# M031AE_v1 register map
File version: 1.0
Registers are 32-bit, read-write, reset 0x0 unless marked. A register's access mark holds for its fields unless they carry their own. Offsets are from the block's base; [hi:lo] are bit positions; 'fields as' and 'values as' point back to an identical list.

## EBI — EBI Register Map
Base 0x40010000
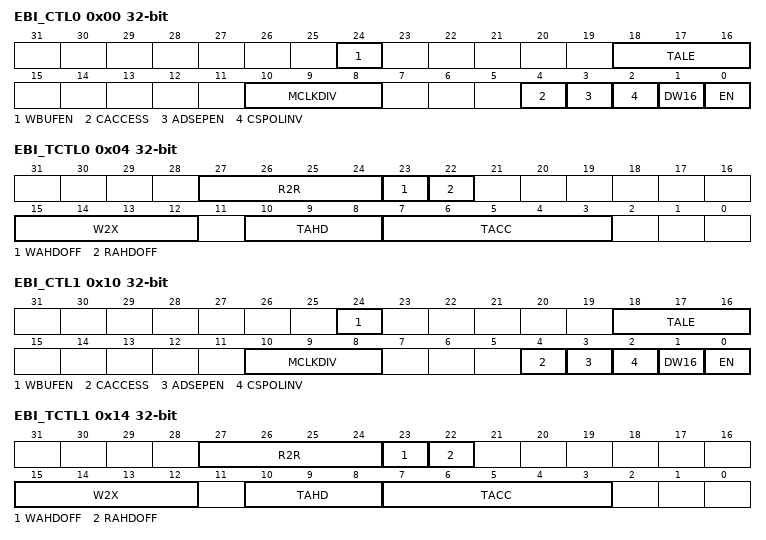
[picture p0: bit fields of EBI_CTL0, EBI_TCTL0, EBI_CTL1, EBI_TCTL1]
0x00 EBI_CTL0 — External Bus Interface Bank0 Control Register
  [24] WBUFEN — EBI Write Buffer Enable Bit. Note: This bit is only available in EBI_CTL0 register.
    0=EBI write buffer Disabled; 1=EBI write buffer Enabled
  [18:16] TALE — Extend Time of ALE. The EBI_ALE high pulse period (tALE) to latch the address can be controlled by TALE. Note: This field is only available in EBI_CTL0 register.
  [10:8] MCLKDIV — External Output Clock Divider. The frequency of EBI output clock (MCLK) is controlled by MCLKDIV as follow:
    0=HCLK/1; 1=HCLK/2; 2=HCLK/4; 3=HCLK/8; 4=HCLK/16; 5=HCLK/32; 6=HCLK/64; 7=HCLK/128
  [4] CACCESS — Continuous Data Access Mode. When Continuous access mode is enabled, the tASU, tALE and tLHD cycles are bypass for continuous data transfer request.
    0=Continuous data access mode Disabled; 1=Continuous data access mode Enabled
  [3] ADSEPEN — EBI Address/Data Bus Separating Mode Enable Bit
    0=Address/Data Bus Separating Mode Disabled; 1=Address/Data Bus Separating Mode Enabled
  [2] CSPOLINV — Chip Select Pin Polar Inverse. This bit defines the active level of EBI chip select pin (EBI_nCS).
    0=Chip select pin (EBI_nCS) is active low; 1=Chip select pin (EBI_nCS) is active high
  [1] DW16 — EBI Data Width 16-bit Select. This bit defines if the EBI data width is 8-bit or 16-bit.
    0=EBI data width is 8-bit; 1=EBI data width is 16-bit
  [0] EN — EBI Enable Bit. This bit is the functional enable bit for EBI.
    0=EBI function Disabled; 1=EBI function Enabled
0x04 EBI_TCTL0 — External Bus Interface Bank0 Timing Control Register
  [27:24] R2R — Idle Cycle Between Read-to-read. This field defines the number of R2R idle cycle. Note: When read action is finished and the next action is going to read, R2R idle cycle is inserted and EBI_nCS return to idle state.
  [23] WAHDOFF — Access Hold Time Disable Control When Write
    0=Data Access Hold Time (tAHD) during EBI writing Enabled; 1=Data Access Hold Time (tAHD) during EBI writing Disabled
  [22] RAHDOFF — Access Hold Time Disable Control When Read
    0=Data Access Hold Time (tAHD) during EBI reading Enabled; 1=Data Access Hold Time (tAHD) during EBI reading Disabled
  [15:12] W2X — Idle Cycle After Write. This field defines the number of W2X idle cycle. Note: When write action is finished, W2X idle cycle is inserted and EBI_nCS return to idle state.
  [10:8] TAHD — EBI Data Access Hold Time. TAHD defines data access hold time (tAHD).
  [7:3] TACC — EBI Data Access Time. TACC defines data access time (tACC).
0x10 EBI_CTL1 — External Bus Interface Bank1 Control Register
  fields as EBI_CTL0
0x14 EBI_TCTL1 — External Bus Interface Bank1 Timing Control Register
  fields as EBI_TCTL0

## CRC — CRC Register Map
Base 0x40031000
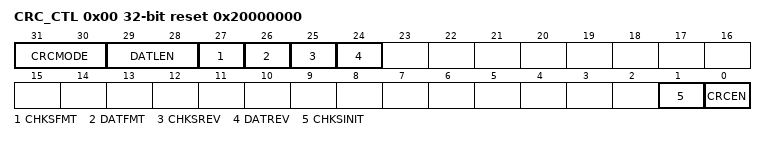
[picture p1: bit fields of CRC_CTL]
0x00 CRC_CTL reset 0x20000000 — CRC Control Register
  [31:30] CRCMODE — CRC Polynomial Mode. This field indicates the CRC operation polynomial mode.
    0=CRC-CCITT Polynomial mode; 1=CRC-8 Polynomial mode; 2=CRC-16 Polynomial mode; 3=CRC-32 Polynomial mode
  [29:28] DATLEN — CPU Write Data Length. This field indicates the write data length. Note: When the write data length is 8-bit mode, the valid data in CRC_DAT register is only DATA[7:0] bits; if the write data length is 16-bit mode, the valid data in CRC_DAT register is only DATA[15:0].
    0=Data length is 8-bit mode; 1=Data length is 16-bit mode. Data length is 32-bit mode
  [27] CHKSFMT — Checksum 1's Complement. This bit is used to enable the 1's complement function for checksum result in CRC_CHECKSUM register.
    0=1's complement for CRC checksum Disabled; 1=1's complement for CRC checksum Enabled
  [26] DATFMT — Write Data 1's Complement. This bit is used to enable the 1's complement function for write data value in CRC_DAT register.
    0=1's complement for CRC writes data in Disabled; 1=1's complement for CRC writes data in Enabled
  [25] CHKSREV — Checksum Bit Order Reverse. This bit is used to enable the bit order reverse function for checksum result in CRC_CHECKSUM register. Note: If the checksum result is 0xDD7B0F2E, the bit order reverse for CRC checksum is 0x74F0DEBB.
    0=Bit order reverse for CRC checksum Disabled; 1=Bit order reverse for CRC checksum Enabled
  [24] DATREV — Write Data Bit Order Reverse. This bit is used to enable the bit order reverse function per byte for write data value in CRC_DAT register. Note: If the write data is 0xAABBCCDD, the bit order reverse for CRC write data in is 0x55DD33BB.
    0=Bit order reversed for CRC write data in Disabled; 1=Bit order reversed for CRC write data in Enabled (per byte)
  [1] CHKSINIT — Checksum Initialization. Note: This bit will be cleared automatically.
    0=No effect; 1=Initial checksum value by auto reload CRC_SEED register value to CRC_CHECKSUM register value
  [0] CRCEN — CRC Channel Enable Bit
    0=No effect; 1=CRC operation Enabled
0x04 CRC_DAT — CRC Write Data Register
  [31:0] DATA — CRC Write Data Bits. User can write data directly by CPU mode or use PDMA function to write data to this field to perform CRC operation. Note: When the write data length is 8-bit mode, the valid data in CRC_DAT register is only DATA[7:0] bits; if the write data length is 16-bit mode, the valid data in CRC_DAT register is only DATA[15:0].
0x08 CRC_SEED reset 0xFFFFFFFF
  [31:0] SEED — CRC Seed Value. This field indicates the CRC seed value. Note: This field will be reloaded as checksum initial value (CRC_CHECKSUM register) after perform CHKSINIT (CRC_CTL[1]).
0x0C CRC_CHECKSUM ro reset 0xFFFFFFFF
  [31:0] CHECKSUM — CRC Checksum Results. This field indicates the CRC checksum result.

## HDIV — HDIV Register Map
Base 0x40014000
0x00 DIVIDEND — Dividend Source Register
  [31:0] DIVIDEND — Dividend Source. This register is given the dividend of divider before calculation starts.
0x04 DIVISOR reset 0xFFFF — Divisor Source Resister
  [15:0] DIVISOR — Divisor Source. This register is provided with the divisor of divider before calculation starts. Note: When this register is written, hardware divider will start calculation.
0x08 DIVQUO — Quotient Result Resister
  [31:0] QUOTIENT — Quotient Result. This register holds the quotient result of divider after calculation is complete.
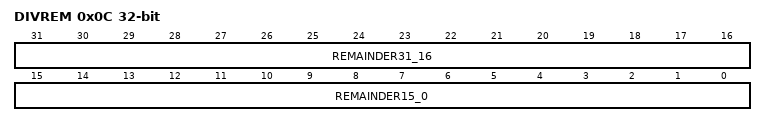
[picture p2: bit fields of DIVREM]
0x0C DIVREM — Remainder Result Register
  [31:16] REMAINDER31_16 — Sign Extension of REMAINDER[15:0]. The remainder of hardware divider is 16-bit sign integer (REMAINDER[15:0]) with sign extension (REMAINDER[31:16]) to 32-bit integer.
  [15:0] REMAINDER15_0 — Remainder Result. This register holds the remainder result of divider after calculation is complete.
0x10 DIVSTS ro reset 0x1 — Divider Status Register
  [1] DIV0 — Divisor Zero Warning (Read Only). Note: The DIV0 flag is used to indicate divide-by-zero situation and updated whenever DIVISOR is written.
    0=The divisor is not 0; 1=The divisor is 0
